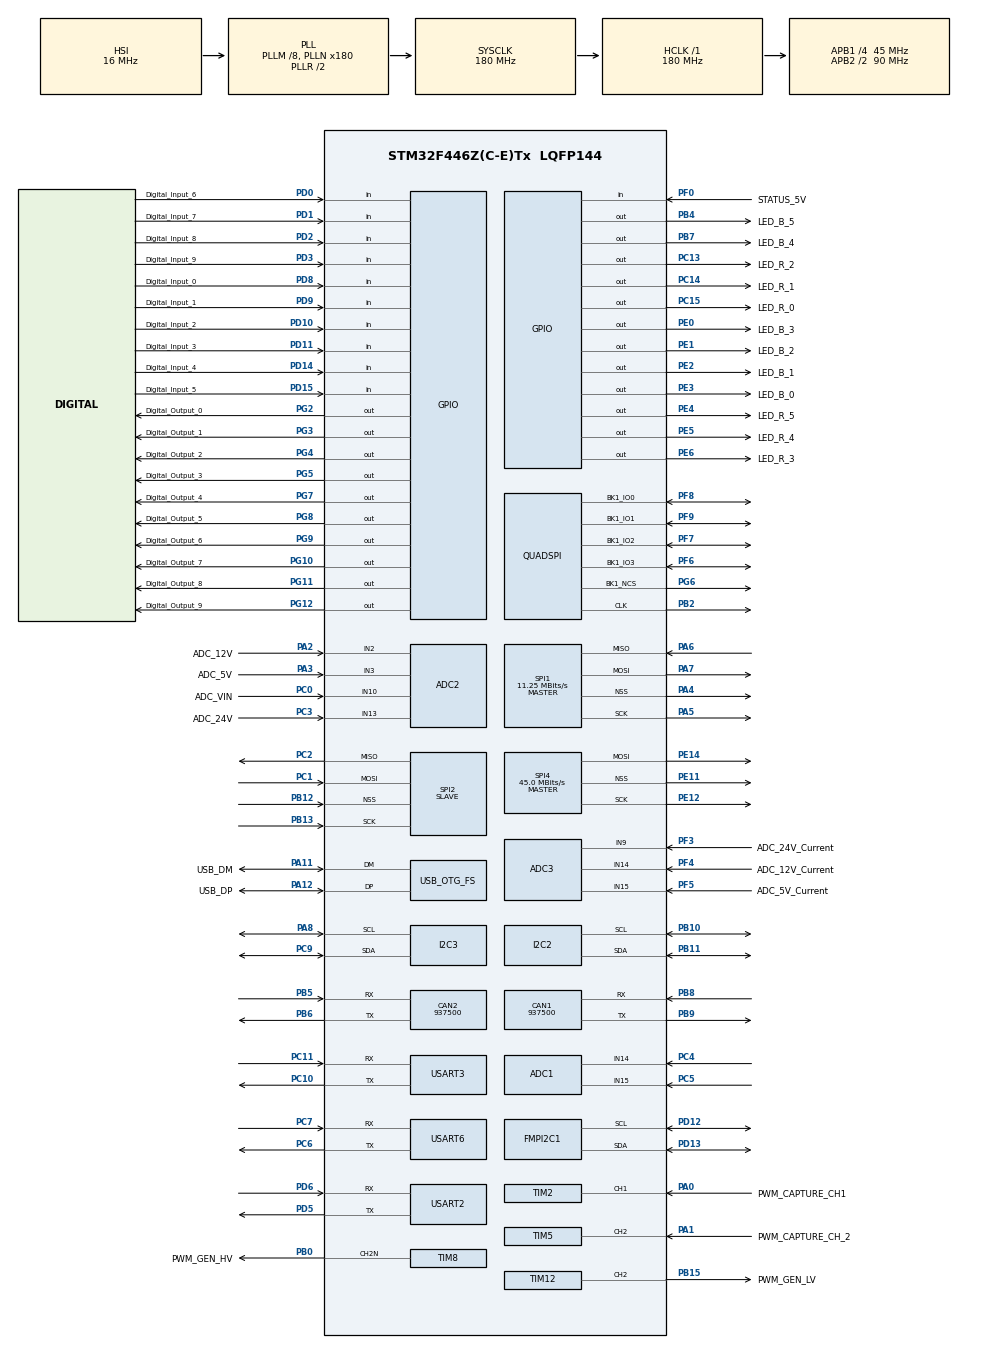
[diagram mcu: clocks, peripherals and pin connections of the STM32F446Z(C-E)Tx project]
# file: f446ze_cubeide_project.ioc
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ADC1.Channel-1\#ChannelRegularConversion=ADC_CHANNEL_14
ADC1.Channel-2\#ChannelRegularConversion=ADC_CHANNEL_15
ADC1.ClockPrescaler=ADC_CLOCK_SYNC_PCLK_DIV6
ADC1.DMAContinuousRequests=ENABLE
ADC1.EOCSelection=ADC_EOC_SEQ_CONV
ADC1.ExternalTrigConv=ADC_EXTERNALTRIGCONV_T3_TRGO
ADC1.NbrOfConversion=2
ADC1.NbrOfConversionFlag=1
ADC1.Rank-1\#ChannelRegularConversion=1
ADC1.Rank-2\#ChannelRegularConversion=2
ADC1.SamplingTime-1\#ChannelRegularConversion=ADC_SAMPLETIME_3CYCLES
ADC1.SamplingTime-2\#ChannelRegularConversion=ADC_SAMPLETIME_3CYCLES
ADC1.ScanConvMode=ENABLE
ADC1.master=1
ADC2.Channel-2\#ChannelRegularConversion=ADC_CHANNEL_2
ADC2.ClockPrescaler=ADC_CLOCK_SYNC_PCLK_DIV6
ADC2.NbrOfConversionFlag=1
ADC2.Rank-2\#ChannelRegularConversion=1
ADC2.SamplingTime-2\#ChannelRegularConversion=ADC_SAMPLETIME_3CYCLES
ADC3.Channel-0\#ChannelRegularConversion=ADC_CHANNEL_9
ADC3.ClockPrescaler=ADC_CLOCK_SYNC_PCLK_DIV6
ADC3.NbrOfConversionFlag=1
ADC3.Rank-0\#ChannelRegularConversion=1
ADC3.SamplingTime-0\#ChannelRegularConversion=ADC_SAMPLETIME_3CYCLES
CAN1.BS1=CAN_BS1_1TQ
CAN1.BS2=CAN_BS2_1TQ
CAN1.CalculateBaudRate=937500
CAN1.CalculateTimeBit=1066
CAN1.CalculateTimeQuantum=355.55555555555554
CAN2.BS1=CAN_BS1_1TQ
CAN2.BS2=CAN_BS2_1TQ
CAN2.CalculateBaudRate=937500
CAN2.CalculateTimeBit=1066
CAN2.CalculateTimeQuantum=355.55555555555554
Dma.ADC1.2.Direction=DMA_PERIPH_TO_MEMORY
Dma.ADC1.2.FIFOMode=DMA_FIFOMODE_DISABLE
Dma.ADC1.2.Instance=DMA2_Stream4
Dma.ADC1.2.MemDataAlignment=DMA_MDATAALIGN_HALFWORD
Dma.ADC1.2.MemInc=DMA_MINC_ENABLE
Dma.ADC1.2.Mode=DMA_CIRCULAR
Dma.ADC1.2.PeriphDataAlignment=DMA_PDATAALIGN_HALFWORD
Dma.ADC1.2.PeriphInc=DMA_PINC_DISABLE
Dma.ADC1.2.Priority=DMA_PRIORITY_LOW
Dma.I2C2_RX.0.Direction=DMA_PERIPH_TO_MEMORY
Dma.I2C2_RX.0.FIFOMode=DMA_FIFOMODE_DISABLE
Dma.I2C2_RX.0.Instance=DMA1_Stream2
Dma.I2C2_RX.0.MemDataAlignment=DMA_MDATAALIGN_BYTE
Dma.I2C2_RX.0.MemInc=DMA_MINC_ENABLE
Dma.I2C2_RX.0.Mode=DMA_NORMAL
Dma.I2C2_RX.0.PeriphDataAlignment=DMA_PDATAALIGN_BYTE
Dma.I2C2_RX.0.PeriphInc=DMA_PINC_DISABLE
Dma.I2C2_RX.0.Priority=DMA_PRIORITY_LOW
Dma.I2C2_TX.1.Direction=DMA_MEMORY_TO_PERIPH
Dma.I2C2_TX.1.FIFOMode=DMA_FIFOMODE_DISABLE
Dma.I2C2_TX.1.Instance=DMA1_Stream7
Dma.I2C2_TX.1.MemDataAlignment=DMA_MDATAALIGN_BYTE
Dma.I2C2_TX.1.MemInc=DMA_MINC_ENABLE
Dma.I2C2_TX.1.Mode=DMA_NORMAL
Dma.I2C2_TX.1.PeriphDataAlignment=DMA_PDATAALIGN_BYTE
Dma.I2C2_TX.1.PeriphInc=DMA_PINC_DISABLE
Dma.I2C2_TX.1.Priority=DMA_PRIORITY_LOW
Dma.QUADSPI.6.Direction=DMA_MEMORY_TO_PERIPH
Dma.QUADSPI.6.FIFOMode=DMA_FIFOMODE_DISABLE
Dma.QUADSPI.6.Instance=DMA2_Stream7
Dma.QUADSPI.6.MemDataAlignment=DMA_MDATAALIGN_BYTE
Dma.QUADSPI.6.MemInc=DMA_MINC_ENABLE
Dma.QUADSPI.6.Mode=DMA_NORMAL
Dma.QUADSPI.6.PeriphDataAlignment=DMA_PDATAALIGN_BYTE
Dma.QUADSPI.6.PeriphInc=DMA_PINC_DISABLE
Dma.QUADSPI.6.Priority=DMA_PRIORITY_LOW
Dma.Request0=I2C2_RX
Dma.Request1=I2C2_TX
Dma.Request10=USART2_TX
Dma.Request11=USART6_RX
Dma.Request12=USART6_TX
Dma.Request2=ADC1
Dma.Request3=SPI4_TX
Dma.Request4=SPI1_TX
Dma.Request5=SPI1_RX
Dma.Request6=QUADSPI
Dma.Request7=SPI2_RX
Dma.Request8=SPI2_TX
Dma.Request9=USART2_RX
Dma.SPI1_RX.5.Direction=DMA_PERIPH_TO_MEMORY
Dma.SPI1_RX.5.FIFOMode=DMA_FIFOMODE_DISABLE
Dma.SPI1_RX.5.Instance=DMA2_Stream0
Dma.SPI1_RX.5.MemDataAlignment=DMA_MDATAALIGN_BYTE
Dma.SPI1_RX.5.MemInc=DMA_MINC_ENABLE
Dma.SPI1_RX.5.Mode=DMA_CIRCULAR
Dma.SPI1_RX.5.PeriphDataAlignment=DMA_PDATAALIGN_BYTE
Dma.SPI1_RX.5.PeriphInc=DMA_PINC_DISABLE
Dma.SPI1_RX.5.Priority=DMA_PRIORITY_LOW
Dma.SPI1_TX.4.Direction=DMA_MEMORY_TO_PERIPH
Dma.SPI1_TX.4.FIFOMode=DMA_FIFOMODE_DISABLE
Dma.SPI1_TX.4.Instance=DMA2_Stream5
Dma.SPI1_TX.4.MemDataAlignment=DMA_MDATAALIGN_BYTE
Dma.SPI1_TX.4.MemInc=DMA_MINC_ENABLE
Dma.SPI1_TX.4.Mode=DMA_NORMAL
Dma.SPI1_TX.4.PeriphDataAlignment=DMA_PDATAALIGN_BYTE
Dma.SPI1_TX.4.PeriphInc=DMA_PINC_DISABLE
Dma.SPI1_TX.4.Priority=DMA_PRIORITY_LOW
Dma.SPI2_RX.7.Direction=DMA_PERIPH_TO_MEMORY
Dma.SPI2_RX.7.FIFOMode=DMA_FIFOMODE_DISABLE
Dma.SPI2_RX.7.Instance=DMA1_Stream3
Dma.SPI2_RX.7.MemDataAlignment=DMA_MDATAALIGN_BYTE
Dma.SPI2_RX.7.MemInc=DMA_MINC_ENABLE
Dma.SPI2_RX.7.Mode=DMA_CIRCULAR
Dma.SPI2_RX.7.PeriphDataAlignment=DMA_PDATAALIGN_BYTE
Dma.SPI2_RX.7.PeriphInc=DMA_PINC_DISABLE
Dma.SPI2_RX.7.Priority=DMA_PRIORITY_HIGH
Dma.SPI2_TX.8.Direction=DMA_MEMORY_TO_PERIPH
Dma.SPI2_TX.8.FIFOMode=DMA_FIFOMODE_DISABLE
Dma.SPI2_TX.8.Instance=DMA1_Stream4
Dma.SPI2_TX.8.MemDataAlignment=DMA_MDATAALIGN_BYTE
Dma.SPI2_TX.8.MemInc=DMA_MINC_ENABLE
Dma.SPI2_TX.8.Mode=DMA_NORMAL
Dma.SPI2_TX.8.PeriphDataAlignment=DMA_PDATAALIGN_BYTE
Dma.SPI2_TX.8.PeriphInc=DMA_PINC_DISABLE
Dma.SPI2_TX.8.Priority=DMA_PRIORITY_HIGH
Dma.SPI4_TX.3.Direction=DMA_MEMORY_TO_PERIPH
Dma.SPI4_TX.3.FIFOMode=DMA_FIFOMODE_DISABLE
Dma.SPI4_TX.3.Instance=DMA2_Stream1
Dma.SPI4_TX.3.MemDataAlignment=DMA_MDATAALIGN_BYTE
Dma.SPI4_TX.3.MemInc=DMA_MINC_ENABLE
Dma.SPI4_TX.3.Mode=DMA_NORMAL
Dma.SPI4_TX.3.PeriphDataAlignment=DMA_PDATAALIGN_BYTE
Dma.SPI4_TX.3.PeriphInc=DMA_PINC_DISABLE
Dma.SPI4_TX.3.Priority=DMA_PRIORITY_HIGH
Dma.USART2_RX.9.Direction=DMA_PERIPH_TO_MEMORY
Dma.USART2_RX.9.FIFOMode=DMA_FIFOMODE_DISABLE
Dma.USART2_RX.9.Instance=DMA1_Stream5
Dma.USART2_RX.9.MemDataAlignment=DMA_MDATAALIGN_BYTE
Dma.USART2_RX.9.MemInc=DMA_MINC_ENABLE
Dma.USART2_RX.9.Mode=DMA_CIRCULAR
Dma.USART2_RX.9.PeriphDataAlignment=DMA_PDATAALIGN_BYTE
Dma.USART2_RX.9.PeriphInc=DMA_PINC_DISABLE
Dma.USART2_RX.9.Priority=DMA_PRIORITY_LOW
Dma.USART2_TX.10.Direction=DMA_MEMORY_TO_PERIPH
Dma.USART2_TX.10.FIFOMode=DMA_FIFOMODE_DISABLE
Dma.USART2_TX.10.Instance=DMA1_Stream6
Dma.USART2_TX.10.MemDataAlignment=DMA_MDATAALIGN_BYTE
Dma.USART2_TX.10.MemInc=DMA_MINC_ENABLE
Dma.USART2_TX.10.Mode=DMA_NORMAL
Dma.USART2_TX.10.PeriphDataAlignment=DMA_PDATAALIGN_BYTE
Dma.USART2_TX.10.PeriphInc=DMA_PINC_DISABLE
Dma.USART2_TX.10.Priority=DMA_PRIORITY_LOW
Dma.USART6_RX.11.Direction=DMA_PERIPH_TO_MEMORY
Dma.USART6_RX.11.FIFOMode=DMA_FIFOMODE_DISABLE
Dma.USART6_RX.11.Instance=DMA2_Stream2
Dma.USART6_RX.11.MemDataAlignment=DMA_MDATAALIGN_BYTE
Dma.USART6_RX.11.MemInc=DMA_MINC_ENABLE
Dma.USART6_RX.11.Mode=DMA_CIRCULAR
Dma.USART6_RX.11.PeriphDataAlignment=DMA_PDATAALIGN_BYTE
Dma.USART6_RX.11.PeriphInc=DMA_PINC_DISABLE
Dma.USART6_RX.11.Priority=DMA_PRIORITY_LOW
Dma.USART6_TX.12.Direction=DMA_MEMORY_TO_PERIPH
Dma.USART6_TX.12.FIFOMode=DMA_FIFOMODE_DISABLE
Dma.USART6_TX.12.Instance=DMA2_Stream6
Dma.USART6_TX.12.MemDataAlignment=DMA_MDATAALIGN_BYTE
Dma.USART6_TX.12.MemInc=DMA_MINC_ENABLE
Dma.USART6_TX.12.Mode=DMA_NORMAL
Dma.USART6_TX.12.PeriphDataAlignment=DMA_PDATAALIGN_BYTE
Dma.USART6_TX.12.PeriphInc=DMA_PINC_DISABLE
Dma.USART6_TX.12.Priority=DMA_PRIORITY_LOW
FMPI2C1.Timing=0xC0000E12
FREERTOS.Tasks01=defaultTask,24,128,StartDefaultTask,Default,NULL,Dynamic,NULL,NULL
FREERTOS.configUSE_NEWLIB_REENTRANT=1
Mcu.Family=STM32F4
Mcu.Name=STM32F446Z(C-E)Tx
Mcu.Package=LQFP144
NVIC.CAN1_RX0_IRQn=true\:5\:0\:false\:false\:true\:true\:true\:true\:true
NVIC.CAN1_TX_IRQn=true\:5\:0\:false\:false\:true\:true\:true\:true\:true
NVIC.CAN2_RX0_IRQn=true\:5\:0\:false\:false\:true\:true\:true\:true\:true
NVIC.CAN2_TX_IRQn=true\:5\:0\:false\:false\:true\:true\:true\:true\:true
NVIC.DMA1_Stream2_IRQn=true\:5\:0\:false\:false\:true\:true\:false\:true\:true
NVIC.DMA1_Stream3_IRQn=true\:5\:0\:false\:false\:true\:true\:false\:true\:true
NVIC.DMA1_Stream4_IRQn=true\:5\:0\:false\:false\:true\:true\:false\:true\:true
NVIC.DMA1_Stream5_IRQn=true\:5\:0\:false\:false\:true\:true\:false\:true\:true
NVIC.DMA1_Stream6_IRQn=true\:5\:0\:false\:false\:true\:true\:false\:true\:true
NVIC.DMA1_Stream7_IRQn=true\:5\:0\:false\:false\:true\:true\:false\:true\:true
NVIC.DMA2_Stream0_IRQn=true\:5\:0\:false\:false\:true\:true\:false\:true\:true
NVIC.DMA2_Stream1_IRQn=true\:5\:0\:false\:false\:true\:true\:false\:true\:true
NVIC.DMA2_Stream2_IRQn=true\:5\:0\:false\:false\:true\:true\:false\:true\:true
NVIC.DMA2_Stream4_IRQn=true\:5\:0\:false\:false\:true\:false\:false\:true\:true
NVIC.DMA2_Stream5_IRQn=true\:5\:0\:false\:false\:true\:true\:false\:true\:true
NVIC.DMA2_Stream6_IRQn=true\:5\:0\:false\:false\:true\:true\:false\:true\:true
NVIC.DMA2_Stream7_IRQn=true\:6\:0\:true\:false\:true\:true\:false\:true\:true
NVIC.FMPI2C1_EV_IRQn=true\:5\:0\:false\:false\:true\:true\:true\:true\:true
NVIC.I2C2_EV_IRQn=true\:5\:0\:false\:false\:true\:true\:true\:true\:true
NVIC.I2C3_EV_IRQn=true\:5\:0\:false\:false\:true\:true\:true\:true\:true
NVIC.OTG_FS_IRQn=true\:5\:0\:false\:false\:true\:true\:false\:true\:true
NVIC.PriorityGroup=NVIC_PRIORITYGROUP_4
NVIC.QUADSPI_IRQn=true\:6\:0\:true\:false\:true\:true\:true\:true\:true
NVIC.TIM1_TRG_COM_TIM11_IRQn=true\:5\:0\:false\:false\:true\:true\:true\:true\:true
NVIC.TIM4_IRQn=true\:5\:0\:false\:false\:true\:true\:true\:true\:true
NVIC.TIM6_DAC_IRQn=true\:5\:0\:false\:false\:true\:true\:true\:true\:true
NVIC.TIM7_IRQn=true\:5\:0\:false\:false\:true\:true\:true\:true\:true
NVIC.TIM8_TRG_COM_TIM14_IRQn=true\:15\:0\:false\:false\:true\:false\:false\:true\:true
NVIC.TimeBase=TIM8_TRG_COM_TIM14_IRQn
NVIC.TimeBaseIP=TIM14
NVIC.USART3_IRQn=true\:5\:0\:false\:false\:true\:true\:true\:true\:true
PA0-WKUP.GPIO_Label=PWM_CAPTURE_CH1
PA0-WKUP.Signal=S_TIM2_CH1_ETR
PA1.GPIO_Label=PWM_CAPTURE_CH_2
PA1.Signal=S_TIM5_CH2
PA11.GPIO_Label=USB_DM
PA11.Mode=Device_Only
PA11.Signal=USB_OTG_FS_DM
PA12.GPIO_Label=USB_DP
PA12.Mode=Device_Only
PA12.Signal=USB_OTG_FS_DP
PA13.GPIO_Label=TMS
PA13.Mode=Trace_Asynchronous_SW
PA13.Signal=SYS_JTMS-SWDIO
PA14.GPIO_Label=TCK
PA14.Mode=Trace_Asynchronous_SW
PA14.Signal=SYS_JTCK-SWCLK
PA2.GPIO_Label=ADC_12V
PA2.Signal=ADCx_IN2
PA3.GPIO_Label=ADC_5V
PA3.Signal=ADCx_IN3
PA4.Mode=NSS_Signal_Hard_Output
PA4.Signal=SPI1_NSS
PA5.Mode=Full_Duplex_Master
PA5.Signal=SPI1_SCK
PA6.Mode=Full_Duplex_Master
PA6.Signal=SPI1_MISO
PA7.Mode=Full_Duplex_Master
PA7.Signal=SPI1_MOSI
PA8.Mode=I2C
PA8.Signal=I2C3_SCL
PB0.GPIO_Label=PWM_GEN_HV
PB0.Mode=PWM Generation2 CH2N
PB0.Signal=TIM8_CH2N
PB10.Mode=I2C
PB10.Signal=I2C2_SCL
PB11.Mode=I2C
PB11.Signal=I2C2_SDA
PB12.Mode=NSS_Signal_Hard_Input
PB12.Signal=SPI2_NSS
PB13.Mode=Full_Duplex_Slave
PB13.Signal=SPI2_SCK
PB15.GPIO_Label=PWM_GEN_LV
PB15.Signal=S_TIM12_CH2
PB2.Mode=Single Bank 1
PB2.Signal=QUADSPI_CLK
PB3.Mode=Trace_Asynchronous_SW
PB3.Signal=SYS_JTDO-SWO
PB4.GPIO_Label=LED_B_5
PB4.Signal=GPIO_Output
PB5.Mode=CAN_Activate
PB5.Signal=CAN2_RX
PB6.Mode=CAN_Activate
PB6.Signal=CAN2_TX
PB7.GPIO_Label=LED_B_4
PB7.Signal=GPIO_Output
PB8.Mode=CAN_Activate
PB8.Signal=CAN1_RX
PB9.Mode=CAN_Activate
PB9.Signal=CAN1_TX
PC0.GPIO_Label=ADC_VIN
PC0.Signal=ADCx_IN10
PC1.Mode=Full_Duplex_Slave
PC1.Signal=SPI2_MOSI
PC10.Mode=Asynchronous
PC10.Signal=USART3_TX
PC11.Mode=Asynchronous
PC11.Signal=USART3_RX
PC13.GPIO_Label=LED_R_2
PC13.Signal=GPIO_Output
PC14-OSC32_IN.GPIO_Label=LED_R_1
PC14-OSC32_IN.Signal=GPIO_Output
PC15-OSC32_OUT.GPIO_Label=LED_R_0
PC15-OSC32_OUT.Signal=GPIO_Output
PC2.Mode=Full_Duplex_Slave
PC2.Signal=SPI2_MISO
PC3.GPIO_Label=ADC_24V
PC3.Signal=ADCx_IN13
PC4.Signal=ADCx_IN14
PC5.Signal=ADCx_IN15
PC6.Mode=Asynchronous
PC6.Signal=USART6_TX
PC7.Mode=Asynchronous
PC7.Signal=USART6_RX
PC9.Mode=I2C
PC9.Signal=I2C3_SDA
PD0.GPIO_Label=Digital_Input_6
PD0.Signal=GPIO_Input
PD1.GPIO_Label=Digital_Input_7
PD1.Signal=GPIO_Input
PD10.GPIO_Label=Digital_Input_2
PD10.Signal=GPIO_Input
PD11.GPIO_Label=Digital_Input_3
PD11.Signal=GPIO_Input
PD12.Mode=I2C
PD12.Signal=FMPI2C1_SCL
PD13.Mode=I2C
PD13.Signal=FMPI2C1_SDA
PD14.GPIO_Label=Digital_Input_4
PD14.Signal=GPIO_Input
PD15.GPIO_Label=Digital_Input_5
PD15.Signal=GPIO_Input
PD2.GPIO_Label=Digital_Input_8
PD2.Signal=GPIO_Input
PD3.GPIO_Label=Digital_Input_9
PD3.Signal=GPIO_Input
PD5.Mode=Asynchronous
PD5.Signal=USART2_TX
PD6.Mode=Asynchronous
PD6.Signal=USART2_RX
PD8.GPIO_Label=Digital_Input_0
PD8.Signal=GPIO_Input
PD9.GPIO_Label=Digital_Input_1
PD9.Signal=GPIO_Input
PE0.GPIO_Label=LED_B_3
PE0.Signal=GPIO_Output
PE1.GPIO_Label=LED_B_2
PE1.Signal=GPIO_Output
PE11.Mode=NSS_Signal_Hard_Output
PE11.Signal=SPI4_NSS
PE12.Mode=TX_Only_Simplex_Unidirect_Master
PE12.Signal=SPI4_SCK
PE14.Mode=TX_Only_Simplex_Unidirect_Master
PE14.Signal=SPI4_MOSI
PE2.GPIO_Label=LED_B_1
PE2.Signal=GPIO_Output
PE3.GPIO_Label=LED_B_0
PE3.Signal=GPIO_Output
PE4.GPIO_Label=LED_R_5
PE4.Signal=GPIO_Output
PE5.GPIO_Label=LED_R_4
PE5.Signal=GPIO_Output
PE6.GPIO_Label=LED_R_3
PE6.Signal=GPIO_Output
PF0.GPIO_Label=STATUS_5V
PF0.Signal=GPIO_Input
PF3.GPIO_Label=ADC_24V_Current
PF3.Mode=IN9
PF3.Signal=ADC3_IN9
PF4.GPIO_Label=ADC_12V_Current
PF4.Mode=IN14
PF4.Signal=ADC3_IN14
PF5.GPIO_Label=ADC_5V_Current
PF5.Mode=IN15
PF5.Signal=ADC3_IN15
PF6.Mode=Single Bank 1
PF6.Signal=QUADSPI_BK1_IO3
PF7.Mode=Single Bank 1
PF7.Signal=QUADSPI_BK1_IO2
PF8.Mode=Single Bank 1
PF8.Signal=QUADSPI_BK1_IO0
PF9.Mode=Single Bank 1
PF9.Signal=QUADSPI_BK1_IO1
PG10.GPIO_Label=Digital_Output_7
PG10.PinState=GPIO_PIN_SET
PG10.Signal=GPIO_Output
PG11.GPIO_Label=Digital_Output_8
PG11.PinState=GPIO_PIN_SET
PG11.Signal=GPIO_Output
PG12.GPIO_Label=Digital_Output_9
PG12.PinState=GPIO_PIN_SET
PG12.Signal=GPIO_Output
PG2.GPIO_Label=Digital_Output_0
PG2.PinState=GPIO_PIN_SET
PG2.Signal=GPIO_Output
PG3.GPIO_Label=Digital_Output_1
PG3.PinState=GPIO_PIN_SET
PG3.Signal=GPIO_Output
PG4.GPIO_Label=Digital_Output_2
PG4.PinState=GPIO_PIN_SET
PG4.Signal=GPIO_Output
PG5.GPIO_Label=Digital_Output_3
PG5.PinState=GPIO_PIN_SET
PG5.Signal=GPIO_Output
PG6.Mode=Single Bank 1
PG6.Signal=QUADSPI_BK1_NCS
PG7.GPIO_Label=Digital_Output_4
PG7.PinState=GPIO_PIN_SET
PG7.Signal=GPIO_Output
PG8.GPIO_Label=Digital_Output_5
PG8.PinState=GPIO_PIN_SET
PG8.Signal=GPIO_Output
PG9.GPIO_Label=Digital_Output_6
PG9.PinState=GPIO_PIN_SET
PG9.Signal=GPIO_Output
PH0-OSC_IN.GPIO_Label=MCO [STM32F103CBT6_PA8]
PH0-OSC_IN.Signal=RCC_OSC_IN
PH1-OSC_OUT.Signal=RCC_OSC_OUT
ProjectManager.HeapSize=0x200
ProjectManager.StackSize=0x400
ProjectManager.TargetToolchain=STM32CubeIDE
QUADSPI.ChipSelectHighTime=QSPI_CS_HIGH_TIME_4_CYCLE
QUADSPI.ClockPrescaler=1
QUADSPI.FifoThreshold=4
QUADSPI.FlashSize=26
RCC.48MHZClocksFreq_Value=24000000
RCC.AHBFreq_Value=180000000
RCC.APB1CLKDivider=RCC_HCLK_DIV4
RCC.APB1Freq_Value=45000000
RCC.APB1TimFreq_Value=90000000
RCC.APB2CLKDivider=RCC_HCLK_DIV2
RCC.APB2Freq_Value=90000000
RCC.APB2TimFreq_Value=180000000
RCC.CortexFreq_Value=180000000
RCC.HCLKFreq_Value=180000000
RCC.HSE_VALUE=16000000
RCC.HSI_VALUE=16000000
RCC.PLLI2SM=32
RCC.PLLM=8
RCC.PLLMUL=RCC_PLL_MUL9
RCC.PLLN=180
RCC.PLLQ=7
RCC.PLLSAIP=RCC_PLLSAIP_DIV4
RCC.PLLSource=RCC_PLLSOURCE_HSI
RCC.PLLSourceVirtual=RCC_PLLSOURCE_HSI
RCC.PRESCALERUSB=RCC_USBCLKSOURCE_PLL_DIV1_5
RCC.SYSCLKFreq_VALUE=180000000
RCC.SYSCLKSource=RCC_SYSCLKSOURCE_PLLRCLK
RCC.SYSCLKSourceVirtual=RCC_SYSCLKSOURCE_PLLCLK
RCC.USBCLockSelection=RCC_CLK48CLKSOURCE_PLLSAIP
RCC.USBFreq_Value=48000000
RCC.VCOOutputFreq_Value=360000000
SH.ADCx_IN10.0=ADC2_IN10,IN10
SH.ADCx_IN13.0=ADC2_IN13,IN13
SH.ADCx_IN14.0=ADC1_IN14,IN14
SH.ADCx_IN15.0=ADC1_IN15,IN15
SH.ADCx_IN2.0=ADC2_IN2,IN2
SH.ADCx_IN3.0=ADC2_IN3,IN3
SH.S_TIM12_CH2.0=TIM12_CH2,PWM Generation2 CH2
SH.S_TIM2_CH1_ETR.0=TIM2_CH1,PWM_Input_1
SH.S_TIM5_CH2.0=TIM5_CH2,PWM_Input_2
SPI1.BaudRatePrescaler=SPI_BAUDRATEPRESCALER_8
SPI1.CalculateBaudRate=11.25 MBits/s
SPI1.Direction=SPI_DIRECTION_2LINES
SPI1.Mode=SPI_MODE_MASTER
SPI1.VirtualNSS=VM_NSSHARD
SPI1.VirtualType=VM_MASTER
SPI2.Direction=SPI_DIRECTION_2LINES
SPI2.Mode=SPI_MODE_SLAVE
SPI2.VirtualNSS=VM_NSSHARD
SPI2.VirtualType=VM_SLAVE
SPI4.BaudRatePrescaler=SPI_BAUDRATEPRESCALER_2
SPI4.CalculateBaudRate=45.0 MBits/s
SPI4.Direction=SPI_DIRECTION_2LINES
SPI4.Mode=SPI_MODE_MASTER
SPI4.VirtualNSS=VM_NSSHARD
SPI4.VirtualType=VM_MASTER
TIM1.Channel-Output\ Compare1\ No\ Output=TIM_CHANNEL_1
TIM12.AutoReloadPreload=TIM_AUTORELOAD_PRELOAD_ENABLE
TIM12.Channel-PWM\ Generation2\ CH2=TIM_CHANNEL_2
TIM2.AutoReloadPreload=TIM_AUTORELOAD_PRELOAD_DISABLE
TIM2.Period=199
TIM2.Prescaler=0
TIM3.Period=899
TIM3.TIM_MasterOutputTrigger=TIM_TRGO_UPDATE
TIM4.Period=8999
TIM4.Prescaler=0
TIM5.ICPolarity_1=TIM_INPUTCHANNELPOLARITY_FALLING
TIM8.AutoReloadPreload=TIM_AUTORELOAD_PRELOAD_ENABLE
TIM8.Channel-PWM\ Generation2\ CH2N=TIM_CHANNEL_2
USART2.VirtualMode=VM_ASYNC
USART3.VirtualMode=VM_ASYNC
USART6.VirtualMode=VM_ASYNC
USB_DEVICE.CLASS_NAME_FS=CDC
USB_DEVICE.PRODUCT_STRING_CDC_FS=HIL-RIG Virtual ComPort
USB_DEVICE.VirtualMode-CDC_FS=Cdc
USB_DEVICE.VirtualModeFS=Cdc_FS
USB_OTG_FS.VirtualMode=Device_Only
VP_CRC_VS_CRC.Mode=CRC_Activate
VP_FREERTOS_VS_CMSIS_V2.Mode=CMSIS_V2
VP_SYS_VS_tim14.Mode=TIM14
VP_TIM11_VS_ClockSourceINT.Mode=Enable_Timer
VP_TIM11_VS_OPM.Mode=OPM_bit
VP_TIM1_VS_no_output1.Mode=Output Compare1 No Output
VP_TIM2_VS_ClockSourceINT.Mode=Internal
VP_TIM3_VS_ClockSourceINT.Mode=Internal
VP_TIM4_VS_ClockSourceINT.Mode=Internal
VP_TIM5_VS_ClockSourceINT.Mode=Internal
VP_TIM6_VS_ClockSourceINT.Mode=Enable_Timer
VP_TIM6_VS_OPM.Mode=OPM_bit
VP_TIM7_VS_ClockSourceINT.Mode=Enable_Timer
VP_TIM7_VS_OPM.Mode=OPM_bit
VP_USB_DEVICE_VS_USB_DEVICE_CDC_FS.Mode=CDC_FS
board=NUCLEO-F446ZE

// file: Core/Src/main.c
/* USER CODE BEGIN Header */
/**
 ******************************************************************************
 * @file           : main.c
 * @brief          : Main program body
 ******************************************************************************
 * @attention
 *
 * Copyright (c) 2025 STMicroelectronics.
 * All rights reserved.
 *
 * This software is licensed under terms that can be found in the LICENSE file
 * in the root directory of this software component.
 * If no LICENSE file comes with this software, it is provided AS-IS.
 *
 ******************************************************************************
 */
/* USER CODE END Header */
#include "main.h"
#include "cmsis_os.h"
#include "adc.h"
#include "can.h"
#include "crc.h"
#include "dma.h"
#include "fmpi2c.h"
#include "i2c.h"
#include "quadspi.h"
#include "spi.h"
#include "tim.h"
#include "usart.h"
#include "usb_device.h"
#include "gpio.h"

/* USER CODE BEGIN Includes */
#include "app_main/app_main.h"
#include "hw_usb.h"
/* USER CODE END Includes */

/* USER CODE BEGIN PD */
#define APP_QSPI_DEFAULT_TIMEOUT_MS ( 100U )
/* USER CODE END PD */

void SystemClock_Config(void);
void MX_FREERTOS_Init(void);

int main(void)
{

  /* MCU Configuration--------------------------------------------------------*/

  /* Reset of all peripherals, Initializes the Flash interface and the Systick. */
  HAL_Init();

  /* Configure the system clock */
  SystemClock_Config();

  /* Initialize all configured peripherals */
  MX_GPIO_Init();
  MX_DMA_Init();
  MX_USART3_UART_Init();
  MX_TIM1_Init();
  MX_ADC1_Init();
  MX_SPI1_Init();
  MX_TIM2_Init();
  MX_FMPI2C1_Init();
  MX_I2C2_Init();
  MX_USART6_UART_Init();
  MX_SPI4_Init();
  MX_QUADSPI_Init();
  MX_CAN1_Init();
  MX_CAN2_Init();
  MX_TIM3_Init();
  MX_TIM4_Init();
  MX_TIM5_Init();
  MX_TIM12_Init();
  MX_TIM6_Init();
  MX_TIM7_Init();
  MX_TIM11_Init();
  MX_SPI2_Init();
  MX_TIM8_Init();
  MX_ADC2_Init();
  MX_ADC3_Init();
  MX_I2C3_Init();
  MX_USART2_UART_Init();
  MX_CRC_Init();
  /* USER CODE BEGIN 2 */

    //  NVIC_DisableIRQ(USART2_IRQn);
    APP_MAIN_Application();
    // Nothing after here is ever called but if it does, run the error handler
    Error_Handler();
  /* USER CODE END 2 */

  /* Init scheduler */
  osKernelInitialize();  /* Call init function for freertos objects (in cmsis_os2.c) */
  MX_FREERTOS_Init();

  /* Start scheduler */
  osKernelStart();

  /* We should never get here as control is now taken by the scheduler */

  /* Infinite loop */
    while ( 1 )
    {

    }
}

void SystemClock_Config(void)
{
  RCC_OscInitTypeDef RCC_OscInitStruct = {0};
  RCC_ClkInitTypeDef RCC_ClkInitStruct = {0};

  /** Configure the main internal regulator output voltage
  */
  __HAL_RCC_PWR_CLK_ENABLE();
  __HAL_PWR_VOLTAGESCALING_CONFIG(PWR_REGULATOR_VOLTAGE_SCALE1);

  /** Initializes the RCC Oscillators according to the specified parameters
  * in the RCC_OscInitTypeDef structure.
  */
  RCC_OscInitStruct.OscillatorType = RCC_OSCILLATORTYPE_HSI;
  RCC_OscInitStruct.HSIState = RCC_HSI_ON;
  /* Reduce HSI trim by three steps; measure residual error before ppm correction. */
  RCC_OscInitStruct.HSICalibrationValue = 13;
  RCC_OscInitStruct.PLL.PLLState = RCC_PLL_ON;
  RCC_OscInitStruct.PLL.PLLSource = RCC_PLLSOURCE_HSI;
  RCC_OscInitStruct.PLL.PLLM = 8;
  RCC_OscInitStruct.PLL.PLLN = 180;
  RCC_OscInitStruct.PLL.PLLP = RCC_PLLP_DIV2;
  RCC_OscInitStruct.PLL.PLLQ = 7;
  RCC_OscInitStruct.PLL.PLLR = 2;
  if (HAL_RCC_OscConfig(&RCC_OscInitStruct) != HAL_OK)
  {
    Error_Handler();
  }

  /** Activate the Over-Drive mode
  */
  if (HAL_PWREx_EnableOverDrive() != HAL_OK)
  {
    Error_Handler();
  }

  /** Initializes the CPU, AHB and APB buses clocks
  */
  RCC_ClkInitStruct.ClockType = RCC_CLOCKTYPE_HCLK|RCC_CLOCKTYPE_SYSCLK
                              |RCC_CLOCKTYPE_PCLK1|RCC_CLOCKTYPE_PCLK2;
  RCC_ClkInitStruct.SYSCLKSource = RCC_SYSCLKSOURCE_PLLRCLK;
  RCC_ClkInitStruct.AHBCLKDivider = RCC_SYSCLK_DIV1;
  RCC_ClkInitStruct.APB1CLKDivider = RCC_HCLK_DIV4;
  RCC_ClkInitStruct.APB2CLKDivider = RCC_HCLK_DIV2;

  if (HAL_RCC_ClockConfig(&RCC_ClkInitStruct, FLASH_LATENCY_5) != HAL_OK)
  {
    Error_Handler();
  }
}

/* USER CODE BEGIN 4 */
extern PCD_HandleTypeDef hpcd_USB_OTG_FS;
extern TIM_HandleTypeDef htim14;

/******************************************************************************/
/*           Cortex-M4 Processor Interruption and Exception Handlers          */
/******************************************************************************/

/**
 * @brief This function handles TIM8 trigger and commutation interrupts and TIM14 global interrupt.
 */
void TIM8_TRG_COM_TIM14_IRQHandler( void )
{
    /* USER CODE BEGIN TIM8_TRG_COM_TIM14_IRQn 0 */

    /* USER CODE END TIM8_TRG_COM_TIM14_IRQn 0 */
    HAL_TIM_IRQHandler( &htim8 );
    HAL_TIM_IRQHandler( &htim14 );
    /* USER CODE BEGIN TIM8_TRG_COM_TIM14_IRQn 1 */

    /* USER CODE END TIM8_TRG_COM_TIM14_IRQn 1 */
}

/**
 * @brief This function handles Non maskable interrupt.
 */
void NMI_Handler( void )
{
    /* USER CODE BEGIN NonMaskableInt_IRQn 0 */

    /* USER CODE END NonMaskableInt_IRQn 0 */
    /* USER CODE BEGIN NonMaskableInt_IRQn 1 */
    while ( 1 )
    {
    }
    /* USER CODE END NonMaskableInt_IRQn 1 */
}

/**
 * @brief This function handles Hard fault interrupt.
 */
void HardFault_Handler( void )
{
    /* USER CODE BEGIN HardFault_IRQn 0 */

    /* USER CODE END HardFault_IRQn 0 */
    while ( 1 )
    {
        /* USER CODE BEGIN W1_HardFault_IRQn 0 */
        /* USER CODE END W1_HardFault_IRQn 0 */
    }
}

/**
 * @brief This function handles Memory management fault.
 */
void MemManage_Handler( void )
{
    /* USER CODE BEGIN MemoryManagement_IRQn 0 */

    /* USER CODE END MemoryManagement_IRQn 0 */
    while ( 1 )
    {
        /* USER CODE BEGIN W1_MemoryManagement_IRQn 0 */
        /* USER CODE END W1_MemoryManagement_IRQn 0 */
    }
}

/**
 * @brief This function handles Pre-fetch fault, memory access fault.
 */
void BusFault_Handler( void )
{
    /* USER CODE BEGIN BusFault_IRQn 0 */

    /* USER CODE END BusFault_IRQn 0 */
    while ( 1 )
    {
        /* USER CODE BEGIN W1_BusFault_IRQn 0 */
        /* USER CODE END W1_BusFault_IRQn 0 */
    }
}

/**
 * @brief This function handles Undefined instruction or illegal state.
 */
void UsageFault_Handler( void )
{
    /* USER CODE BEGIN UsageFault_IRQn 0 */

    /* USER CODE END UsageFault_IRQn 0 */
    while ( 1 )
    {
        /* USER CODE BEGIN W1_UsageFault_IRQn 0 */
        /* USER CODE END W1_UsageFault_IRQn 0 */
    }
}

/**
 * @brief This function handles Debug monitor.
 */
void DebugMon_Handler( void )
{
    /* USER CODE BEGIN DebugMonitor_IRQn 0 */

    /* USER CODE END DebugMonitor_IRQn 0 */
    /* USER CODE BEGIN DebugMonitor_IRQn 1 */

    /* USER CODE END DebugMonitor_IRQn 1 */
}

/**
 * @brief This function handles USB On The Go FS global interrupt.
 */
void OTG_FS_IRQHandler( void )
{
    /* USER CODE BEGIN OTG_FS_IRQn 0 */

    /* USER CODE END OTG_FS_IRQn 0 */
    HAL_PCD_IRQHandler( &hpcd_USB_OTG_FS );
    /* USER CODE BEGIN OTG_FS_IRQn 1 */

    /* USER CODE END OTG_FS_IRQn 1 */
}

/* USER CODE END 4 */

void HAL_TIM_PeriodElapsedCallback(TIM_HandleTypeDef *htim)
{
  if (htim->Instance == TIM14)
  {
    HAL_IncTick();
  }
}

void Error_Handler(void)
{
    __disable_irq();
    while ( 1 )
    {
    }
}
